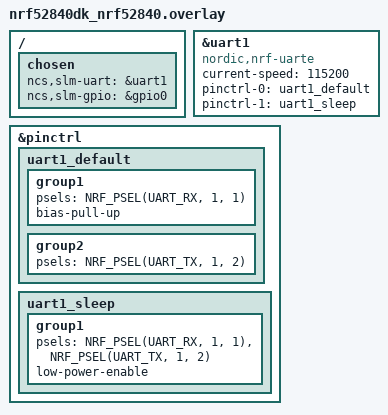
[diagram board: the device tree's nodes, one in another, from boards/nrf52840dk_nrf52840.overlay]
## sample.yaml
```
sample:
  description: SLM shell sample
  name: slm shell
tests:
  sample.cellular.slm_shell:
    sysbuild: true
    build_only: true
    integration_platforms:
      - nrf52840dk/nrf52840
      - nrf5340dk/nrf5340/cpuapp
      - nrf7002dk/nrf5340/cpuapp
    platform_allow: nrf52840dk/nrf52840 nrf5340dk/nrf5340/cpuapp nrf7002dk/nrf5340/cpuapp
    tags: ci_build sysbuild ci_samples_cellular
```

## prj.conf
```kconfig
#
# Copyright (c) 2023 Nordic Semiconductor ASA
#
# SPDX-License-Identifier: LicenseRef-Nordic-5-Clause
#

CONFIG_STACK_SENTINEL=y
CONFIG_MAIN_STACK_SIZE=4096
CONFIG_HEAP_MEM_POOL_SIZE=8192

CONFIG_LOG=y
CONFIG_LOG_BACKEND_UART=y
CONFIG_CONSOLE=y
CONFIG_UART_CONSOLE=y
CONFIG_SHELL=y
CONFIG_SHELL_WILDCARD=n
CONFIG_SHELL_ARGC_MAX=40
CONFIG_SHELL_CMD_BUFF_SIZE=1024
CONFIG_SHELL_STACK_SIZE=1024
CONFIG_SHELL_LOG_BACKEND=n

CONFIG_SERIAL=y
CONFIG_UART_ASYNC_API=y

CONFIG_MODEM_SLM=y
CONFIG_MODEM_SLM_SHELL=y
CONFIG_MODEM_SLM_LOG_LEVEL_INF=y
```

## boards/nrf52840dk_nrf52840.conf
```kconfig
#
# Copyright (c) 2023 Nordic Semiconductor ASA
#
# SPDX-License-Identifier: LicenseRef-Nordic-5-Clause
#

# Configuration file for nRF52840DK.
# This file is merged with prj.conf in the application folder, and options
# set here will take precedence if they are present in both files.

CONFIG_NRFX_UARTE1=y
CONFIG_UART_1_INTERRUPT_DRIVEN=n
CONFIG_UART_1_ASYNC=y
CONFIG_UART_1_NRF_HW_ASYNC=y
CONFIG_UART_1_NRF_HW_ASYNC_TIMER=2
CONFIG_MODEM_SLM_WAKEUP_PIN=11
CONFIG_MODEM_SLM_INDICATE_PIN=13
```

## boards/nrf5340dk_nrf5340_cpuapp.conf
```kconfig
#
# Copyright (c) 2023 Nordic Semiconductor ASA
#
# SPDX-License-Identifier: LicenseRef-Nordic-5-Clause
#

# Configuration file for nRF53400DK.
# This file is merged with prj.conf in the application folder, and options
# set here will take precedence if they are present in both files.

CONFIG_NRFX_UARTE2=y
CONFIG_UART_2_INTERRUPT_DRIVEN=n
CONFIG_UART_2_ASYNC=y
CONFIG_UART_2_NRF_HW_ASYNC=y
CONFIG_UART_2_NRF_HW_ASYNC_TIMER=2
CONFIG_MODEM_SLM_WAKEUP_PIN=23
```

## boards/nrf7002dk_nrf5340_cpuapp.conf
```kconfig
#
# Copyright (c) 2023 Nordic Semiconductor ASA
#
# SPDX-License-Identifier: LicenseRef-Nordic-5-Clause
#

# Configuration file for nRF7002DK.
# This file is merged with prj.conf in the application folder, and options
# set here will take precedence if they are present in both files.

CONFIG_NRFX_UARTE2=y
CONFIG_UART_2_INTERRUPT_DRIVEN=n
CONFIG_UART_2_ASYNC=y
CONFIG_UART_2_NRF_HW_ASYNC=y
CONFIG_UART_2_NRF_HW_ASYNC_TIMER=2
CONFIG_MODEM_SLM_WAKEUP_PIN=30
CONFIG_MODEM_SLM_INDICATE_PIN=31
```

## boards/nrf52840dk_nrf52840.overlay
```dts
/*
 * Copyright (c) 2023 Nordic Semiconductor ASA
 *
 * SPDX-License-Identifier: LicenseRef-Nordic-5-Clause
 */

/ {
	chosen {
		ncs,slm-uart = &uart1;
		ncs,slm-gpio = &gpio0;
	};
};

&uart1 {
	compatible = "nordic,nrf-uarte";
	current-speed = <115200>;
	status = "okay";

	pinctrl-0 = <&uart1_default>;
	pinctrl-1 = <&uart1_sleep>;
	pinctrl-names = "default", "sleep";
};

&pinctrl {
	uart1_default: uart1_default {
		group1 {
			psels = <NRF_PSEL(UART_RX, 1, 1)>;
			bias-pull-up;
		};
		group2 {
			psels = <NRF_PSEL(UART_TX, 1, 2)>;
		};
	};

	uart1_sleep: uart1_sleep {
		group1 {
			psels = <NRF_PSEL(UART_RX, 1, 1)>,
				<NRF_PSEL(UART_TX, 1, 2)>;
			low-power-enable;
		};
	};
};
```

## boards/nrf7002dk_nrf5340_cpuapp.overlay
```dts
/*
 * Copyright (c) 2023 Nordic Semiconductor ASA
 *
 * SPDX-License-Identifier: LicenseRef-Nordic-5-Clause
 */

/ {
	chosen {
		ncs,slm-uart = &uart2;
		ncs,slm-gpio = &gpio0;
	};
};

&uart2 {
	compatible = "nordic,nrf-uarte";
	current-speed = <115200>;
	status = "okay";

	pinctrl-0 = <&uart2_default>;
	pinctrl-1 = <&uart2_sleep>;
	pinctrl-names = "default", "sleep";
};

&pinctrl {
	uart2_default: uart2_default {
		group1 {
			psels = <NRF_PSEL(UART_TX, 1, 4)>;
		};
		group2 {
			psels = <NRF_PSEL(UART_RX, 1, 5)>;
			bias-pull-up;
		};
	};

	uart2_sleep: uart2_sleep {
		group1 {
			psels = <NRF_PSEL(UART_TX, 1, 4)>,
				<NRF_PSEL(UART_RX, 1, 5)>;
			low-power-enable;
		};
	};
};
```

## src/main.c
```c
/*
 * Copyright (c) 2023 Nordic Semiconductor ASA
 *
 * SPDX-License-Identifier: LicenseRef-Nordic-5-Clause
 */

#include <stdlib.h>
#include <modem/modem_slm.h>
#include <zephyr/logging/log.h>

LOG_MODULE_REGISTER(app, CONFIG_LOG_DEFAULT_LEVEL);

SLM_MONITOR(network, "\r\n+CEREG:", cereg_mon);

static void cereg_mon(const char *notif)
{
	int status = atoi(notif + strlen("\r\n+CEREG: "));

	if (status == 1 || status == 5) {
		LOG_INF("LTE connected");
	}
}

int main(void)
{
	LOG_INF("SLM Shell starts on %s", CONFIG_BOARD);

	(void)modem_slm_init(NULL);
	return 0;
}
```
